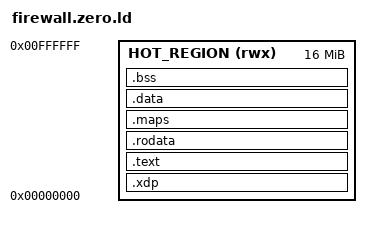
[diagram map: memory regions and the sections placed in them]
/* Proposed zero-address linker script, generated by phase 1. */
helper_dispatcher = 0;
MEMORY { HOT_REGION (rwx) : ORIGIN = 0, LENGTH = 0x1000000 }
ENTRY(_start)
SECTIONS
{
    .xdp : ALIGN(4) { _start = .; *(xdp) *(xdp1) *(.xdp) *(.xdp.*) } > HOT_REGION
    .text : ALIGN(4) { *(.text) *(.text.*) } > HOT_REGION
    .rodata : ALIGN(4) { *(.rodata) *(.rodata.*) *(.srodata) *(.srodata.*) *(license) } > HOT_REGION
    .maps : ALIGN(4) { *(.maps) *(maps) } > HOT_REGION
    .data : ALIGN(4) { *(.data) *(.data.*) *(.sdata) *(.sdata.*) } > HOT_REGION
    .bss : ALIGN(4) { *(.bss) *(.bss.*) *(.sbss) *(.sbss.*) *(COMMON) } > HOT_REGION
    /DISCARD/ : { *(.eh_frame) *(.comment) *(.note*) *(.riscv.attributes) *(.relaxdp) }
}
